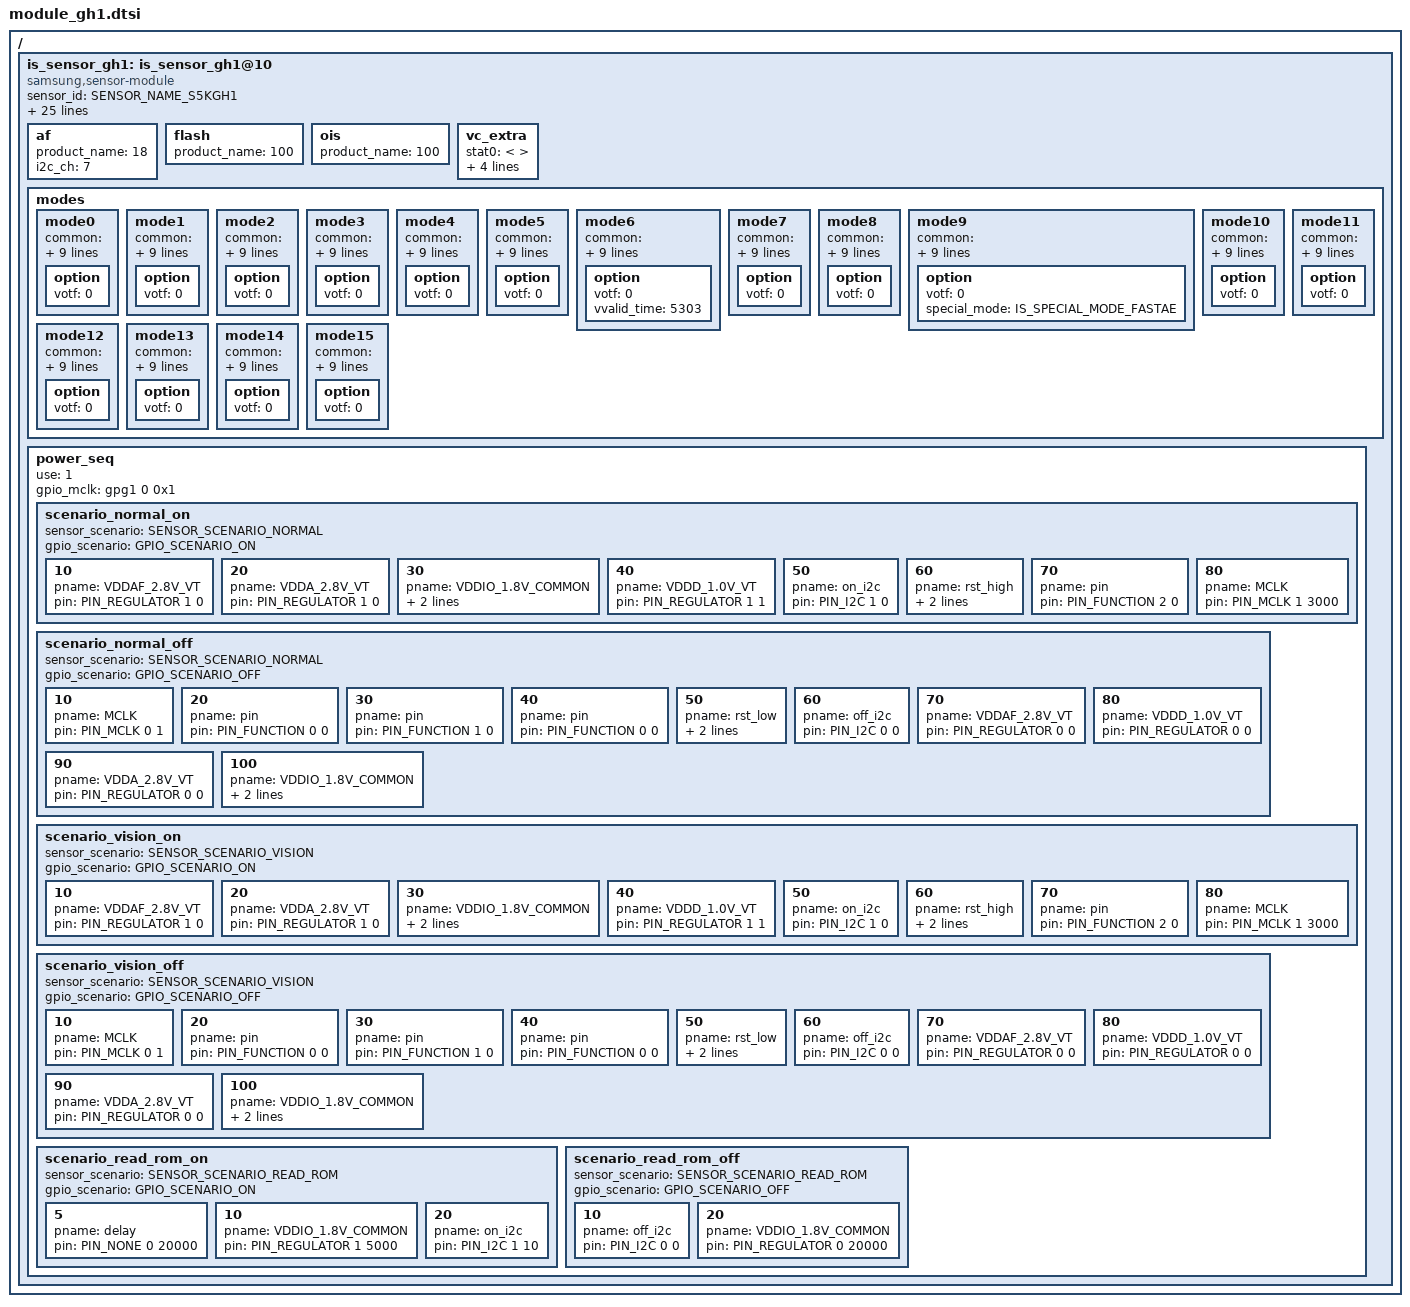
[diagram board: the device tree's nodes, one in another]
/*
 * SAMSUNG EXYNOSxxxx board camera device tree source
 *
 * Copyright (c) 2019 Samsung Electronics Co., Ltd.
 *		http://www.samsung.com
 *
 * This program is free software; you can redistribute it and/or modify
 * it under the terms of the GNU General Public License version 2 as
 * published by the Free Software Foundation.
 */

#include <dt-bindings/camera/exynos_is_dt.h>

/* GH1 sensor setting version - S5KGH1SM16_EVT0_ver_1.7 */
/* Global setting */
/* sensor_gh1_setfile_A_Global */

/* Mode setting */
/* D1	19.2Mhz_7296x5472_1299Msps_15FPS MIPI lane: 4, MIPI data rate(Mbps/lane): 1299.1, MIPI Mclk(Mhz): 19.2 PD tail off */
/* D13	19.2Mhz_3648x2736_1395Msps_30FPS MIPI lane: 4, MIPI data rate(Mbps/lane): 1395.1, MIPI Mclk(Mhz): 19.2  */
/* D14	19.2Mhz_3968x2232_1299Msps_30FPS MIPI lane: 4, MIPI data rate(Mbps/lane): 1299.1, MIPI Mclk(Mhz): 19.2 */
/* D4	19.2Mhz_3968x2232_1517Msps_60FPS MIPI lane: 4, MIPI data rate(Mbps/lane): 1516.7, MIPI Mclk(Mhz): 19.2 */
/* D5	19.2Mhz_1984x1116_1299Msps_240FPS MIPI lane: 4, MIPI data rate(Mbps/lane): 1299.1, MIPI Mclk(Mhz): 19.2 PD tail off */
/* D6	19.2Mhz_1824x1368_1299Msps_30FPS MIPI lane: 4, MIPI data rate(Mbps/lane): 1299.1, MIPI Mclk(Mhz): 19.2 */
/* D7	19.2Mhz_1984x1116_1299Msps_30FPS MIPI lane: 4, MIPI data rate(Mbps/lane): 1299.1, MIPI Mclk(Mhz): 19.2 */
/* D9	19.2Mhz_2944x2208_1395Msps_30FPS MIPI lane: 4, MIPI data rate(Mbps/lane): 1395.1, MIPI Mclk(Mhz): 19.2 */
/* D10	19.2Mhz_3216x1808_1299Msps_30FPS MIPI lane: 4, MIPI data rate(Mbps/lane): 1299.1, MIPI Mclk(Mhz): 19.2 */
/* D11	19.2Mhz_912x684_1299Msps_119FPS MIPI lane: 4, MIPI data rate(Mbps/lane): 1299.1, MIPI Mclk(Mhz): 19.2, PD tail off */
/* D12	19.2Mhz_3968x2232_2125Msps_120FPS MIPI lane: 4, MIPI data rate(Mbps/lane): 2124.7, MIPI Mclk(Mhz): 19.2 PD tail off */
/* D15	19.2Mhz_3216x2208_1299Msps_30FPS MIPI lane: 4, MIPI data rate(Mbps/lane): 1299.1, MIPI Mclk(Mhz): 19.2 */
/* D17	19.2Mhz_3648x2736_1395Msps_60FPS MIPI lane: 4, MIPI data rate(Mbps/lane): 1395.1, MIPI Mclk(Mhz): 19.2 */
/* D18	19.2Mhz_1472x1104_1299Msps_30FPS MIPI lane: 4, MIPI data rate(Mbps/lane): 1299.1, MIPI Mclk(Mhz): 19.2 */
/* F1	19.2Mhz_3648x2736_1395Msps_30FPS MIPI lane: 4, MIPI data rate(Mbps/lane): 1395.2, MIPI Mclk(Mhz): 19.2 PD tail off, FD mode */
/* F2	19.2Mhz_3648x2736_1395Msps_30FPS MIPI lane: 4, MIPI data rate(Mbps/lane): 1395.2, MIPI Mclk(Mhz): 19.2 PD tail on, FD mode */

/ {
	fragment@camera {
		target-path = "/";
		__overlay__ {
			is_sensor_gh1: is_sensor_gh1@10 {
				compatible = "samsung,sensor-module";

				/* common */
				sensor_id = <SENSOR_NAME_S5KGH1>;
				active_width = <7968>;
				active_height = <5480>;
				margin_left = <0>;
				margin_right = <0>;
				margin_top = <0>;
				margin_bottom = <0>;
				max_framerate = <240>;
				bitwidth = <10>;
				use_retention_mode = <SENSOR_RETENTION_UNSUPPORTED>;
				sensor_maker = "SLSI";
				sensor_name = "S5KGH1";
				setfile_name = "setfile_gh1.bin";

				status = "okay";

				/* board */
				pinctrl-names = "pin0", "pin1", "pin2", "release";
				pinctrl-0 = <>;
				pinctrl-1 = <&sensor_mclk0_out>;
				pinctrl-2 = <&sensor_mclk0_fn>;
				pinctrl-3 = <>;

				position = <1>;	/* Rear:0. Front:1. Rear_sub:2. Secure:3. */
				id = <1>; /* is_sensor id */
				mclk_ch = <0>;
				mclk_freq = <19200>;
				sensor_i2c_ch = <6>; /* SENSOR_CONTROL_I2C6 */

				/* vendor */
				rom_type = <2>; /* ROM_TYPE_EEPROM */
				rom_id = <1>;
				rom_cal_index = <0>;

				/* peri*/
				af {
					product_name = <18>; /* ACTUATOR_NAME_AK737X */
					i2c_ch = <7>; /* SENSOR_CONTROL_I2C7 */
				};

				flash {
					product_name = <100>; /* NOTHING */
				};

				ois {
					product_name = <100>; /* NOTHING */
				};

				vc_extra {
					/* ex) statX = <stat_type, sensor_mode, max_width, max_height, max_element> */
					stat0 = </* not available */>;			/* VC_BUF_DATA_TYPE_SENSOR_STAT1 */
					stat1 = </*VC_STAT_TYPE_PDP_4_1_PDAF_STAT0*/ 1200 /* VC_SENSOR_MODE_SUPER_PD_3_TAIL */ 405 496 2720 2>; /* VC_BUF_DATA_TYPE_GENERAL_STAT1 */
					stat2 = </* not available */>;			/* VC_BUF_DATA_TYPE_SENSOR_STAT2 */
					stat3 = </*VC_STAT_TYPE_PDP_4_1_PDAF_STAT1*/ 1201 /* VC_SENSOR_MODE_SUPER_PD_3_TAIL */ 405 496 2720 2>; /* VC_BUF_DATA_TYPE_GENERAL_STAT2 */
					stat_vc = <2>; /* STAT out VC after CSIS link */
				};

				/* sensor modes */
				modes {
						/* common = <width, height, fps, settle, mode, lane, speed, interleave, lrte, pd_mode> */
						/* vcX = <map, hwformat, width, height, hwformat, type, width, height> */
					mode0 {/* D1	19.2Mhz_7296x5472_1299Msps_15FPS MIPI lane: 4, MIPI data rate(Mbps/lane): 1299.1, MIPI Mclk(Mhz): 19.2 PD tail off */
						common = <7296 5472 15 0 0 CSI_DATA_LANES_3 1299 CSI_MODE_VC_ONLY LRTE_ENABLE PD_NONE EX_NONE>;
						vc0 = </* in */ 0 HW_FORMAT_RAW10 7296 5472	/* out */ HW_FORMAT_RAW10 VC_NOTHING 7296 5472>;
						vc1 = </* in */ 1 HW_FORMAT_UNKNOWN 0 0	/* out */ HW_FORMAT_UNKNOWN VC_NOTHING 0 0>;
						vc2 = </* in */ 2 HW_FORMAT_UNKNOWN 0 0	/* out */ HW_FORMAT_UNKNOWN VC_NOTHING 0 0>;
						vc3 = </* in */ 3 HW_FORMAT_UNKNOWN 0 0	/* out */ HW_FORMAT_UNKNOWN VC_NOTHING 0 0>;
						option { votf = <0>; };
					};
					mode1 {/* D13	19.2Mhz_3648x2736_1395Msps_30FPS MIPI lane: 4, MIPI data rate(Mbps/lane): 1395.1, MIPI Mclk(Mhz): 19.2  */
						common = <3648 2736 30 0 1 CSI_DATA_LANES_3 1395 CSI_MODE_VC_ONLY LRTE_ENABLE PD_MSPD_TAIL EX_NONE>;
						vc0 = </* in */ 0 HW_FORMAT_RAW10 3648 2736	/* out */ HW_FORMAT_RAW10 VC_NOTHING 3648 2736>;
						vc1 = </* in */ 2 HW_FORMAT_UNKNOWN 0 0	/* out */ HW_FORMAT_UNKNOWN VC_NOTHING 0 0>;
						vc2 = </* in */ 1 HW_FORMAT_RAW10_POTF 456 2720	/* out */ HW_FORMAT_RAW10_POTF VC_TAILPDAF 456 2720>;
						vc3 = </* in */ 3 HW_FORMAT_UNKNOWN 0 0	/* out */ HW_FORMAT_UNKNOWN VC_NOTHING 0 0>;
						option { votf = <0>; };
					};
					mode2 {/* D14	19.2Mhz_3968x2232_1299Msps_30FPS MIPI lane: 4, MIPI data rate(Mbps/lane): 1299.1, MIPI Mclk(Mhz): 19.2 */
						common = <3968 2232 30 0 2 CSI_DATA_LANES_3 1299 CSI_MODE_VC_ONLY LRTE_ENABLE PD_MSPD_TAIL>;
						vc0 = </* in */ 0 HW_FORMAT_RAW10 3968 2232 	/* out */ HW_FORMAT_RAW10 VC_NOTHING 3968 2232>;
						vc1 = </* in */ 2 HW_FORMAT_UNKNOWN 0 0	/* out */ HW_FORMAT_UNKNOWN VC_NOTHING 0 0>;
						vc2 = </* in */ 1 HW_FORMAT_RAW10_POTF 496 2192	/* out */ HW_FORMAT_RAW10_POTF VC_TAILPDAF 496 2192>;
						vc3 = </* in */ 3 HW_FORMAT_UNKNOWN 0 0	/* out */ HW_FORMAT_UNKNOWN VC_NOTHING 0 0>;
						option { votf = <0>; };
					};
					mode3 {/* D4	19.2Mhz_3968x2232_1517Msps_60FPS MIPI lane: 4, MIPI data rate(Mbps/lane): 1516.7, MIPI Mclk(Mhz): 19.2 */
						common = <3968 2232 60 0 3 CSI_DATA_LANES_3 1517 CSI_MODE_VC_ONLY LRTE_ENABLE PD_MSPD_TAIL>;
						vc0 = </* in */ 0 HW_FORMAT_RAW10 3968 2232	/* out */ HW_FORMAT_RAW10 VC_NOTHING 3968 2232>;
						vc1 = </* in */ 2 HW_FORMAT_UNKNOWN 0 0	/* out */ HW_FORMAT_UNKNOWN VC_NOTHING 0 0>;
						vc2 = </* in */ 1 HW_FORMAT_RAW10_POTF 496 2192	/* out */ HW_FORMAT_RAW10_POTF VC_TAILPDAF 496 2192>;
						vc3 = </* in */ 3 HW_FORMAT_UNKNOWN 0 0	/* out */ HW_FORMAT_UNKNOWN VC_NOTHING 0 0>;
						option { votf = <0>; };
					};
					mode4 {/* D5	19.2Mhz_1984x1116_1299Msps_240FPS MIPI lane: 4, MIPI data rate(Mbps/lane): 1299.1, MIPI Mclk(Mhz): 19.2 PD tail off */
						common = <1984 1116 240 0 4 CSI_DATA_LANES_3 1299 CSI_MODE_VC_ONLY LRTE_ENABLE PD_NONE>;
						vc0 = </* in */ 0 HW_FORMAT_RAW10 1984 1116	/* out */ HW_FORMAT_RAW10 VC_NOTHING 1984 1116>;
						vc1 = </* in */ 1 HW_FORMAT_UNKNOWN 0 0	/* out */ HW_FORMAT_UNKNOWN VC_NOTHING 0 0>;
						vc2 = </* in */ 2 HW_FORMAT_UNKNOWN 0 0	/* out */ HW_FORMAT_UNKNOWN VC_NOTHING 0 0>;
						vc3 = </* in */ 3 HW_FORMAT_UNKNOWN 0 0	/* out */ HW_FORMAT_UNKNOWN VC_NOTHING 0 0>;
						option { votf = <0>; };
					};
					mode5 {/* D6	19.2Mhz_1824x1368_1299Msps_30FPS MIPI lane: 4, MIPI data rate(Mbps/lane): 1299.1, MIPI Mclk(Mhz): 19.2 */
						common = <1824 1368 30 0 5 CSI_DATA_LANES_3 1299 CSI_MODE_VC_ONLY LRTE_ENABLE PD_MSPD_TAIL>;
						vc0 = </* in */ 0 HW_FORMAT_RAW10 1824 1368	/* out */ HW_FORMAT_RAW10 VC_NOTHING 1824 1368>;
						vc1 = </* in */ 2 HW_FORMAT_UNKNOWN 0 0	/* out */ HW_FORMAT_UNKNOWN VC_NOTHING 0 0>;
						vc2 = </* in */ 1 HW_FORMAT_RAW10_POTF 456 680	/* out */ HW_FORMAT_RAW10_POTF VC_TAILPDAF 456 680>;
						vc3 = </* in */ 3 HW_FORMAT_UNKNOWN 0 0	/* out */ HW_FORMAT_UNKNOWN VC_NOTHING 0 0>;
						option { votf = <0>; };
					};
					mode6 {/* D7	19.2Mhz_1984x1116_1299Msps_30FPS MIPI lane: 4, MIPI data rate(Mbps/lane): 1299.1, MIPI Mclk(Mhz): 19.2 */
						common = <1984 1116 30 0 6 CSI_DATA_LANES_3 1299 CSI_MODE_VC_ONLY LRTE_ENABLE PD_MSPD_TAIL>;
						vc0 = </* in */ 0 HW_FORMAT_RAW10 1984 1116 	/* out */ HW_FORMAT_RAW10 VC_NOTHING 1984 1116>;
						vc1 = </* in */ 2 HW_FORMAT_UNKNOWN 0 0	/* out */ HW_FORMAT_UNKNOWN VC_NOTHING 0 0>;
						vc2 = </* in */ 1 HW_FORMAT_RAW10_POTF 496 552	/* out */ HW_FORMAT_RAW10_POTF VC_TAILPDAF 496 552>;
						vc3 = </* in */ 3 HW_FORMAT_UNKNOWN 0 0	/* out */ HW_FORMAT_UNKNOWN VC_NOTHING 0 0>;
						option { votf = <0>; vvalid_time = <5303>; };
					};
					mode7 {/* D9	19.2Mhz_2944x2208_1395Msps_30FPS MIPI lane: 4, MIPI data rate(Mbps/lane): 1395.1, MIPI Mclk(Mhz): 19.2 */
						common = <2944 2208 30 0 7 CSI_DATA_LANES_3 1395 CSI_MODE_VC_ONLY LRTE_ENABLE PD_MSPD_TAIL>;
						vc0 = </* in */ 0 HW_FORMAT_RAW10 2944 2208	/* out */ HW_FORMAT_RAW10 VC_NOTHING 2944 2208>;
						vc1 = </* in */ 2 HW_FORMAT_UNKNOWN 0 0	/* out */ HW_FORMAT_UNKNOWN VC_NOTHING 0 0>;
						vc2 = </* in */ 1 HW_FORMAT_RAW10_POTF 368 2192	/* out */ HW_FORMAT_RAW10_POTF VC_TAILPDAF 368 2192>;
						vc3 = </* in */ 3 HW_FORMAT_UNKNOWN 0 0	/* out */ HW_FORMAT_UNKNOWN VC_NOTHING 0 0>;
						option { votf = <0>; };
					};
					mode8 {/* D10	19.2Mhz_3216x1808_1299Msps_30FPS MIPI lane: 4, MIPI data rate(Mbps/lane): 1299.1, MIPI Mclk(Mhz): 19.2 */
						common = <3216 1808 30 0 8 CSI_DATA_LANES_3 1299 CSI_MODE_VC_ONLY LRTE_ENABLE PD_MSPD_TAIL>;
						vc0 = </* in */ 0 HW_FORMAT_RAW10 3216 1808	/* out */ HW_FORMAT_RAW10 VC_NOTHING 3216 1808>;
						vc1 = </* in */ 2 HW_FORMAT_UNKNOWN 0 0	/* out */ HW_FORMAT_UNKNOWN VC_NOTHING 0 0>;
						vc2 = </* in */ 1 HW_FORMAT_RAW10_POTF 400 1776	/* out */ HW_FORMAT_RAW10_POTF VC_TAILPDAF 400 1776>;
						vc3 = </* in */ 3 HW_FORMAT_UNKNOWN 0 0	/* out */ HW_FORMAT_UNKNOWN VC_NOTHING 0 0>;
						option { votf = <0>; };
					};
					mode9 {/* D11	19.2Mhz_912x684_1299Msps_119FPS MIPI lane: 4, MIPI data rate(Mbps/lane): 1299.1, MIPI Mclk(Mhz): 19.2, PD tail off */
						common = <912 684 119 0 9 CSI_DATA_LANES_3 1299 CSI_MODE_VC_ONLY LRTE_DISABLE PD_NONE>;
						vc0 = </* in */ 0 HW_FORMAT_RAW10 912 684	/* out */ HW_FORMAT_RAW10 VC_NOTHING 912 684>;
						vc1 = </* in */ 1 HW_FORMAT_UNKNOWN 0 0	/* out */ HW_FORMAT_UNKNOWN VC_NOTHING 0 0>;
						vc2 = </* in */ 2 HW_FORMAT_UNKNOWN 0 0	/* out */ HW_FORMAT_UNKNOWN VC_NOTHING 0 0>;
						vc3 = </* in */ 3 HW_FORMAT_UNKNOWN 0 0	/* out */ HW_FORMAT_UNKNOWN VC_NOTHING 0 0>;
						option { votf = <0>; special_mode = <IS_SPECIAL_MODE_FASTAE>; };
					};
					mode10 {/* D12	19.2Mhz_3968x2232_2125Msps_120FPS MIPI lane: 4, MIPI data rate(Mbps/lane): 2124.7, MIPI Mclk(Mhz): 19.2 PD tail off */
						common = <3968 2232 120 0 10 CSI_DATA_LANES_3 2125 CSI_MODE_VC_ONLY LRTE_ENABLE PD_NONE>;
						vc0 = </* in */ 0 HW_FORMAT_RAW10 3968 2232	/* out */ HW_FORMAT_RAW10 VC_NOTHING 3968 2232>;
						vc1 = </* in */ 1 HW_FORMAT_UNKNOWN 0 0	/* out */ HW_FORMAT_UNKNOWN VC_NOTHING 0 0>;
						vc2 = </* in */ 2 HW_FORMAT_UNKNOWN 0 0	/* out */ HW_FORMAT_UNKNOWN VC_NOTHING 0 0>;
						vc3 = </* in */ 3 HW_FORMAT_UNKNOWN 0 0	/* out */ HW_FORMAT_UNKNOWN VC_NOTHING 0 0>;
						option { votf = <0>; };
					};
					mode11 {/* D15	19.2Mhz_3216x2208_1299Msps_30FPS MIPI lane: 4, MIPI data rate(Mbps/lane): 1299.1, MIPI Mclk(Mhz): 19.2 */
						common = <3216 2208 30 0 11 CSI_DATA_LANES_3 1299 CSI_MODE_VC_ONLY LRTE_ENABLE PD_MSPD_TAIL>;
						vc0 = </* in */ 0 HW_FORMAT_RAW10 3216 2208 	/* out */ HW_FORMAT_RAW10 VC_NOTHING 3216 2208>;
						vc1 = </* in */ 2 HW_FORMAT_UNKNOWN 0 0	/* out */ HW_FORMAT_UNKNOWN VC_NOTHING 0 0>;
						vc2 = </* in */ 1 HW_FORMAT_RAW10_POTF 400 2192	/* out */ HW_FORMAT_RAW10_POTF VC_TAILPDAF 400 2192>;
						vc3 = </* in */ 3 HW_FORMAT_UNKNOWN 0 0	/* out */ HW_FORMAT_UNKNOWN VC_NOTHING 0 0>;
						option { votf = <0>; };
					};
					mode12 {/* F1	19.2Mhz_3648x2736_1395Msps_30FPS MIPI lane: 4, MIPI data rate(Mbps/lane): 1395.2, MIPI Mclk(Mhz): 19.2 PD tail off, FD mode */
						common = <3648 2736 30 0 1 CSI_DATA_LANES_3 1395 CSI_MODE_VC_ONLY LRTE_ENABLE PD_NONE EX_PDAF_OFF>;
						vc0 = </* in */ 0 HW_FORMAT_RAW10 3648 2736	/* out */ HW_FORMAT_RAW10 VC_NOTHING 1824 1368>;
						vc1 = </* in */ 2 HW_FORMAT_UNKNOWN 0 0	/* out */ HW_FORMAT_UNKNOWN VC_NOTHING 0 0>;
						vc2 = </* in */ 1 HW_FORMAT_UNKNOWN 0 0	/* out */ HW_FORMAT_UNKNOWN VC_NOTHING 0 0>;
						vc3 = </* in */ 3 HW_FORMAT_UNKNOWN 0 0	/* out */ HW_FORMAT_UNKNOWN VC_NOTHING 0 0>;
						option { votf = <0>; };
					};
					mode13 {/* C2	26Mhz_3648x2736_1398Msps_30FPS MIPI lane: 4, MIPI data rate(Mbps/lane): 1397.5, MIPI Mclk(Mhz): 26 REMOSIC PREVIEW */
						common = <3648 2736 30 0 1 CSI_DATA_LANES_3 1398 CSI_MODE_VC_ONLY LRTE_ENABLE PD_MSPD_TAIL EX_REMOSAIC_CAL>;
						vc0 = </* in */ 0 HW_FORMAT_RAW10 3648 2736	/* out */ HW_FORMAT_RAW10 VC_NOTHING 3648 2736>;
						vc1 = </* in */ 2 HW_FORMAT_UNKNOWN 0 0	/* out */ HW_FORMAT_UNKNOWN VC_NOTHING 0 0>;
						vc2 = </* in */ 1 HW_FORMAT_RAW10_POTF 456 2720	/* out */ HW_FORMAT_RAW10_POTF VC_TAILPDAF 456 2720>;
						vc3 = </* in */ 3 HW_FORMAT_UNKNOWN 0 0	/* out */ HW_FORMAT_UNKNOWN VC_NOTHING 0 0>;
						option { votf = <0>; };
					};
					mode14 {/* D17	19.2Mhz_3648x2736_1395Msps_60FPS MIPI lane: 4, MIPI data rate(Mbps/lane): 1395.1, MIPI Mclk(Mhz): 19.2 */
						common = <3648 2736 60 0 15 CSI_DATA_LANES_3 1395 CSI_MODE_VC_ONLY LRTE_ENABLE PD_MSPD_TAIL>;
						vc0 = </* in */ 0 HW_FORMAT_RAW10 3648 2736	/* out */ HW_FORMAT_RAW10 VC_NOTHING 3648 2736>;
						vc1 = </* in */ 2 HW_FORMAT_UNKNOWN 0 0	/* out */ HW_FORMAT_UNKNOWN VC_NOTHING 0 0>;
						vc2 = </* in */ 1 HW_FORMAT_RAW10_POTF 456 2720	/* out */ HW_FORMAT_RAW10_POTF VC_TAILPDAF 456 2720>;
						vc3 = </* in */ 3 HW_FORMAT_UNKNOWN 0 0	/* out */ HW_FORMAT_UNKNOWN VC_NOTHING 0 0>;
						option { votf = <0>; };
					};
					mode15 {/* D18	19.2Mhz_1472x1104_1299Msps_30FPS MIPI lane: 4, MIPI data rate(Mbps/lane): 1299.1, MIPI Mclk(Mhz): 19.2 */
						common = <1472 1104 30 0 16 CSI_DATA_LANES_3 1299 CSI_MODE_VC_ONLY LRTE_ENABLE PD_MSPD_TAIL>;
						vc0 = </* in */ 0 HW_FORMAT_RAW10 1472 1104	/* out */ HW_FORMAT_RAW10 VC_NOTHING 1472 1104>;
						vc1 = </* in */ 2 HW_FORMAT_UNKNOWN 0 0	/* out */ HW_FORMAT_UNKNOWN VC_NOTHING 0 0>;
						vc2 = </* in */ 1 HW_FORMAT_RAW10_POTF 368 552	/* out */ HW_FORMAT_RAW10_POTF VC_TAILPDAF 368 552>;
						vc3 = </* in */ 3 HW_FORMAT_UNKNOWN 0 0	/* out */ HW_FORMAT_UNKNOWN VC_NOTHING 0 0>;
						option { votf = <0>; };
					};
				};

				power_seq {
					use = <1>;
					gpio_mclk = <&gpg1 0 0x1>;
					scenario_normal_on {
						sensor_scenario = <SENSOR_SCENARIO_NORMAL>;
						gpio_scenario = <GPIO_SCENARIO_ON>;

						/* A start node number should be over the 10 for reserved number 0~9. */
						/* pname = "name"; pin = <act value dealy voltage>; gpio = <gpx# # 0x1>; */
						10 { pname = "VDDAF_2.8V_VT"; pin = <PIN_REGULATOR 1 0>; };
						20 { pname = "VDDA_2.8V_VT"; pin = <PIN_REGULATOR 1 0>; };
						30 { pname = "VDDIO_1.8V_COMMON"; pin = <PIN_REGULATOR 1 0>; share = <SRT_ACQUIRE SHARED_PIN0 1>; };
						40 { pname = "VDDD_1.0V_VT"; pin = <PIN_REGULATOR 1 1>; };
						50 { pname = "on_i2c"; pin = <PIN_I2C 1 0>; };
						60 { pname = "rst_high"; pin = <PIN_OUTPUT 1 10>; gpio = <&gpg0 1 0x1>; };
						70 { pname = "pin"; pin = <PIN_FUNCTION 2 0>; };
						80 { pname = "MCLK"; pin = <PIN_MCLK 1 3000>; };
					};

					scenario_normal_off {
						sensor_scenario = <SENSOR_SCENARIO_NORMAL>;
						gpio_scenario = <GPIO_SCENARIO_OFF>;

						/* A start node number should be over the 10 for reserved number 0~9. */
						/* pname = "name"; pin = <act value dealy voltage>; gpio = <gpx# # 0x1>; */
						10 { pname = "MCLK"; pin = <PIN_MCLK 0 1>; };
						20 { pname = "pin"; pin = <PIN_FUNCTION 0 0>; };
						30 { pname = "pin"; pin = <PIN_FUNCTION 1 0>; };
						40 { pname = "pin"; pin = <PIN_FUNCTION 0 0>; };
						50 { pname = "rst_low"; pin = <PIN_OUTPUT 0 0>; gpio = <&gpg0 1 0x1>; };
						60 { pname = "off_i2c"; pin = <PIN_I2C 0 0>; };
						70 { pname = "VDDAF_2.8V_VT"; pin = <PIN_REGULATOR 0 0>; };
						80 { pname = "VDDD_1.0V_VT"; pin = <PIN_REGULATOR 0 0>; };
						90 { pname = "VDDA_2.8V_VT"; pin = <PIN_REGULATOR 0 0>; };
						100 { pname = "VDDIO_1.8V_COMMON"; pin = <PIN_REGULATOR 0 0>; share = <SRT_RELEASE SHARED_PIN0 0>; };
					};

					scenario_vision_on {
						sensor_scenario = <SENSOR_SCENARIO_VISION>;
						gpio_scenario = <GPIO_SCENARIO_ON>;

						/* A start node number should be over the 10 for reserved number 0~9. */
						/* pname = "name"; pin = <act value dealy voltage>; gpio = <gpx# # 0x1>; */
						10 { pname = "VDDAF_2.8V_VT"; pin = <PIN_REGULATOR 1 0>; };
						20 { pname = "VDDA_2.8V_VT"; pin = <PIN_REGULATOR 1 0>; };
						30 { pname = "VDDIO_1.8V_COMMON"; pin = <PIN_REGULATOR 1 0>; share = <SRT_ACQUIRE SHARED_PIN0 1>; };
						40 { pname = "VDDD_1.0V_VT"; pin = <PIN_REGULATOR 1 1>; };
						50 { pname = "on_i2c"; pin = <PIN_I2C 1 0>; };
						60 { pname = "rst_high"; pin = <PIN_OUTPUT 1 10>; gpio = <&gpg0 1 0x1>; };
						70 { pname = "pin"; pin = <PIN_FUNCTION 2 0>; };
						80 { pname = "MCLK"; pin = <PIN_MCLK 1 3000>; };
					};

					scenario_vision_off {
						sensor_scenario = <SENSOR_SCENARIO_VISION>;
						gpio_scenario = <GPIO_SCENARIO_OFF>;

						/* A start node number should be over the 10 for reserved number 0~9. */
						/* pname = "name"; pin = <act value dealy voltage>; gpio = <gpx# # 0x1>; */
						10 { pname = "MCLK"; pin = <PIN_MCLK 0 1>; };
						20 { pname = "pin"; pin = <PIN_FUNCTION 0 0>; };
						30 { pname = "pin"; pin = <PIN_FUNCTION 1 0>; };
						40 { pname = "pin"; pin = <PIN_FUNCTION 0 0>; };
						50 { pname = "rst_low"; pin = <PIN_OUTPUT 0 0>; gpio = <&gpg0 1 0x1>; };
						60 { pname = "off_i2c"; pin = <PIN_I2C 0 0>; };
						70 { pname = "VDDAF_2.8V_VT"; pin = <PIN_REGULATOR 0 0>; };
						80 { pname = "VDDD_1.0V_VT"; pin = <PIN_REGULATOR 0 0>; };
						90 { pname = "VDDA_2.8V_VT"; pin = <PIN_REGULATOR 0 0>; };
						100 { pname = "VDDIO_1.8V_COMMON"; pin = <PIN_REGULATOR 0 0>; share = <SRT_RELEASE SHARED_PIN0 0>; };
					};

					scenario_read_rom_on {
						sensor_scenario = <SENSOR_SCENARIO_READ_ROM>;
						gpio_scenario = <GPIO_SCENARIO_ON>;

						/* A start node number should be over the 10 for reserved number 0~9. */
						/* pname = "name"; pin = <act value dealy voltage>; gpio = <gpx# # 0x1>; */
						5 { pname = "delay"; pin = <PIN_NONE 0 20000>; };
						10 { pname = "VDDIO_1.8V_COMMON"; pin = <PIN_REGULATOR 1 5000>; };
						20 { pname = "on_i2c"; pin = <PIN_I2C 1 10>; };
					};

					scenario_read_rom_off {
						sensor_scenario = <SENSOR_SCENARIO_READ_ROM>;
						gpio_scenario = <GPIO_SCENARIO_OFF>;

						/* A start node number should be over the 10 for reserved number 0~9. */
						/* pname = "name"; pin = <act value dealy voltage>; gpio = <gpx# # 0x1>; */
						10 { pname = "off_i2c"; pin = <PIN_I2C 0 0>; };
						20 { pname = "VDDIO_1.8V_COMMON"; pin = <PIN_REGULATOR 0 20000>; };
					};
				};
			};
		}; /* end of __overlay__ */
	}; /* end of fragment */
}; /* end of root */
